# axi-ethernet register map
File version: 7.2
axi-ethernet device descript
Registers are 32-bit, read-only, reset 0x0 unless marked. A register's access mark holds for its fields unless they carry their own. Offsets are from the block's base; lines under a group give offsets from that group; [hi:lo] are bit positions; {n}, {i} and the like mark numbered series; 'fields as' and 'values as' point back to an identical list; <NAME> marks a mode.

## Memory map
0x60110000 AXI_ETHERNET size 0x10000 — AXI Ethernet MAC

## AXI_ETHERNET — AXI Ethernet MAC
Base 0x60110000
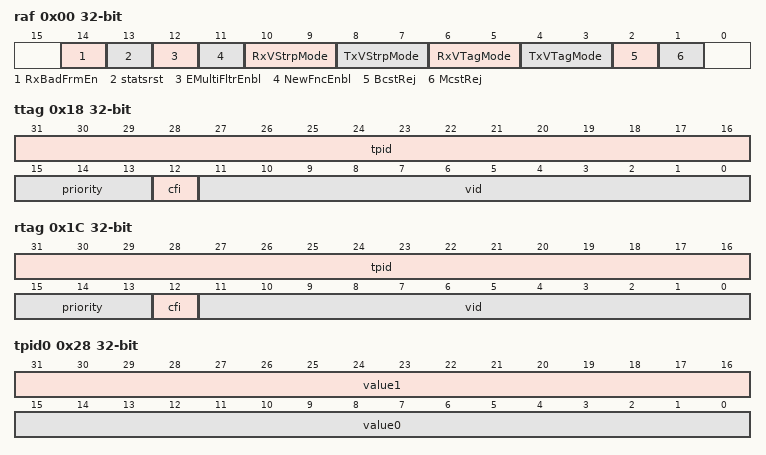
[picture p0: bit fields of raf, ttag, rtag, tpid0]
0x00 raf rw — Reset and Address Filter TEMAC
  [14] RxBadFrmEn
    0=DISABLE; 1=ENABLE
  [13] statsrst
    0=DISABLE; 1=ENABLE
  [12] EMultiFltrEnbl
    0=DISABLE; 1=ENABLE
  [11] NewFncEnbl
    0=DISABLE; 1=ENABLE
  [10:9] RxVStrpMode
    0=NO_VLAN; 1=ONE_VLAN_FROM_ALL; 3=ONE_VLAN_FROM_SELECT
  [8:7] TxVStrpMode
    0=NO_VLAN; 1=ONE_VLAN_FROM_ALL; 3=ONE_VLAN_FROM_SELECT
  [6:5] RxVTagMode
    0=NO_VLAN; 1=ONE_VLAN_FROM_ALL; 2=ONE_VLAN_FROM_ALL_HAVE; 3=ONE_VLAN_FROM_SELECT
  [4:3] TxVTagMode
    values as RxVTagMode
  [2] BcstRej
    0=ACCEPT; 1=REJECT
  [1] McstRej
    0=ACCEPT; 1=REJECT
0x04 tpf rw — Transmit Pause Frame TEMAC
  [15:0] TPFV
    0=RESET
0x08 ifgp rw — Transmit Inter Frame Gap Adjustment TEMAC
  [7:0] IFGP0
    0=RESET
0x0C is rw — Interrupt Status
  [8] PhyRstCmplt
    0=NOT_READY; 1=READY
  [7] MgtRdy
    0=NOT_READY; 1=READY
  [6] RxDcmLock
    0=NOT_LOCKED; 1=LOCKED
  [5] TxCmplt
    0=NO_FRAME; 1=HAS_FRAME
  [4] RxFIFOOvr
    0=NORMAL; 1=OVERFLOW
  [3] RxRject
    0=NO_REJECT; 1=HAS_REJECT
  [2] RxCmplt
    0=NO_FRAME; 1=HAS_FRAME
  [1] AutoNeg
    0=NOT_COMPLETE; 1=COMPLETE
  [0] HardAcsCmplt
    0=NOT_COMPLETE; 1=COMPLETE
  [5:0] All
0x10 ip — Interrupt Pending
  fields as is
0x14 ie rw — Interrupt Enable
  [8] PhyRstCmplt
    0=DISABLE; 1=ENABLE
  [7] MgtRdy
    0=DISABLE; 1=ENABLE
  [6] RxDcmLock
    0=DISABLE; 1=ENABLE
  [5] TxCmplt
    0=DISABLE; 1=ENABLE
  [4] RxFIFOOvr
    0=DISABLE; 1=ENABLE
  [3] RxRject
    0=DISABLE; 1=ENABLE
  [2] RxCmplt
    0=DISABLE; 1=ENABLE
  [1] AutoNeg
    0=DISABLE; 1=ENABLE
  [0] HardAcsCmplt
    0=DISABLE; 1=ENABLE
  [5:0] All
0x18 ttag rw — Transmit VLAN Tag TEMAC
  [all] fields
    0=RESET
  [31:16] tpid
  [15:13] priority
  [12] cfi
  [11:0] vid
0x1C rtag rw — Receive VLAN Tag TEMAC
  fields as ttag
0x20 uawl rw — Unicast Address Word Lower TEMAC
  [31:0] UnicastAddr
    0=RESET
0x24 uawu rw — Unicast Address Word Upper TEMAC
  [15:0] UnicastAddr
    0=RESET
0x28 tpid0 rw — VLAN TPID TEMAC Word 0
  [31:16] value1
    0=RESET
  [15:0] value0
    0=RESET
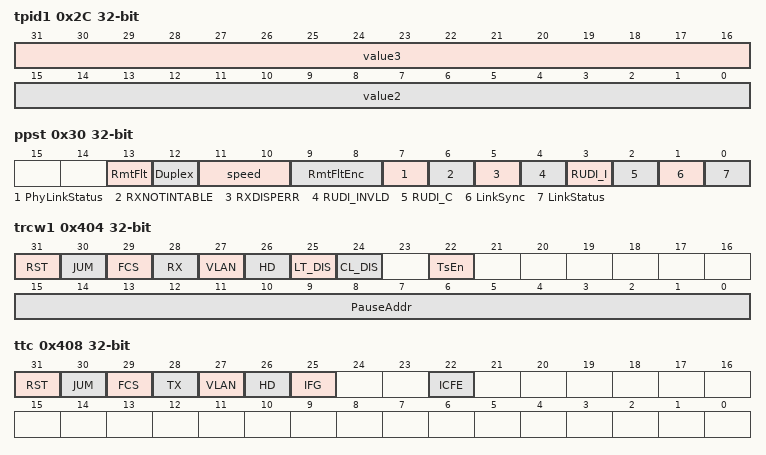
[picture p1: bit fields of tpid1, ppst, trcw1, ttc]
0x2C tpid1 rw — VLAN TPID TEMAC Word 1
  [31:16] value3
    0=RESET
  [15:0] value2
    0=RESET
0x30 ppst — PCS PMA TEMAC Status
  [13] RmtFlt
    0=RESET
  [12] Duplex
    0=HALF_DUPLEX; 1=FULL_DUPLEX
  [11:10] speed
    2=1000M; 1=100M; 0=10M
  [9:8] RmtFltEnc
    0=RESET
  [7] PhyLinkStatus
    0=RESET
  [6] RXNOTINTABLE
    0=RESET
  [5] RXDISPERR
    0=RESET
  [4] RUDI_INVLD
    0=RESET
  [3] RUDI_I
    0=RESET
  [2] RUDI_C
    0=RESET
  [1] LinkSync
    0=RESET
  [0] LinkStatus
    0=RESET
0x200 rxbl — Received Bytes, LSW
0x204 rxbu — Received Bytes, MSW
0x208 txbl — Transmitted Bytes, LSW
0x20C txbu — Transmitted Bytes, MSW
0x210 rxundrl — Count of undersize frames received, LSM
0x214 rxundru — Count of undersize frames received, MSM
0x218 rxfragl — Count of undersize and bad FCS frames received, LSM
0x21C rxfragu — Count of undersize and bad FCS frames received, MSM
0x220 rx64bl — Count of 64 bytes frames received, LSM
0x224 rx64bu — Count of 64 bytes frames received, MSM
0x228 rx65b127l — Count of 65-127 bytes frames received, LSM
0x22C rx65b127u — Count of 65-127 bytes frames received, MSM
0x230 rx128b255l — Count of 128-255 bytes frames received, LSM
0x234 rx128b255u — Count of 128-255 bytes frames received, MSM
0x238 rx256b511l — Count of 256-511 bytes frames received, LSM
0x23C rx256b511u — Count of 256-511 bytes frames received, MSM
0x240 rx512b1023l — Count of 512-1023 bytes frames received, LSM
0x244 rx512b1023u — Count of 512-1023 bytes frames received, MSM
0x248 rx1024bl — Count of 1024-MAX bytes frames received, LSM
0x24C rx1024bu — Count of 1024-MAX bytes frames received, MSM
0x250 rxovrl — Count of oversize frames received, LSM
0x254 rxovru — Count of oversize bytes frames received, MSM
0x258 tx64bl — Count of 64 bytes frames transmitted, LSM
0x25C tx64bu — Count of 64 bytes frames transmitted, MSM
0x260 tx65b127l — Count of 65-127 bytes frames transmitted, LSM
0x264 tx65b127u — Count of 65-127 bytes frames transmitted, MSM
0x268 tx128b255l — Count of 128-255 bytes frames transmitted, LSM
0x26C tx128b255u — Count of 128-255 bytes frames transmitted, MSM
0x270 tx256b511l — Count of 256-511 bytes frames transmitted, LSM
0x274 tx256b511u — Count of 256-511 bytes frames transmitted, MSM
0x278 tx512b1023l — Count of 512-1023 bytes frames transmitted, LSM
0x27C tx512b1023u — Count of 512-1023 bytes frames transmitted, MSM
0x280 tx1024bl — Count of 1024-MAX bytes frames transmitted, LSM
0x284 tx1024bu — Count of 1024-MAX bytes frames transmitted, MSM
0x288 txovrl — Count of oversize frames transmitted, LSM
0x28C txovru — Count of oversize bytes frames transmitted, MSM
0x290 rxfl — Count of frames received OK, LSM
0x294 rxfu — Count of frames transmitted OK, MSM
0x298 rxfcserl — Count of frames received with FCS error and at least 64 bytes, LSM
0x29C rxfcseru — Count of frames received with FCS error and at least 64 bytes, MSM
0x2A0 rxbcstfl — Count of broadcast frames received, LSM
0x2A4 rxbcstfu — Count of broadcast frames received, MSM
0x2A8 rxmcstfl — Count of multicast frames received, LSM
0x2AC rxmcstfu — Count of multicast frames received, MSM
0x2B0 rxctrfl — Count of control frames received, LSM
0x2B4 rxctrfu — Count of control frames received, MSM
0x2B8 rxlterl — Count of frames received with length error, LSM
0x2BC rxlteru — Count of frames received with length error, MSM
0x2C0 rxvlanfl — Count of VLAN tagged frames received, LSM
0x2C4 rxvlanfu — Count of VLAN tagged frames received, MSM
0x2C8 rxpfl — Count of pause frames received, LSM
0x2CC rxpfu — Count of pause frames received, MSM
0x2D0 rxuopfl — Count of control frames received with unsupported opcode, LSM
0x2D4 rxuopfu — Count of control frames received with unsupported opcode, MSM
0x2D8 txfl — Count of frames transmitted OK, LSM
0x2DC txfu — Count of frames transmitted OK, MSM
0x2E0 txbcstfl — Count of broadcast frames transmitted, LSM
0x2E4 txbcstfu — Count of broadcast frames transmitted, MSM
0x2E8 txmcstfl — Count of multicast frames transmitted, LSM
0x2EC txmcstfu — Count of multicast frames transmitted, MSM
0x2F0 txundererl — Count of frames transmitted underrun error, LSM
0x2F4 txundereru — Count of frames transmitted underrun error, MSM
0x2F8 txctrfl — Count of control frames transmitted, LSM
0x2FC txctrfu — Count of control frames transmitted, MSM
0x300 txvlanfl — Count of VLAN tagged frames transmitted, LSM
0x304 txvlanfu — Count of VLAN tagged frames transmitted, MSM
0x308 txpfl — Count of pause frames transmitted, LSM
0x30C txpfu — Count of pause frames transmitted, MSM
0x310 txscl — Single Collision frames transmitted OK, LSM
0x314 txscu — Single Collision frames transmitted OK, MSM
0x318 txmcl — Multiple Collision Frames Transmitted OK, LSM
0x31C txmcu — Multiple Collision frames Transmitted OK, MSM
0x320 txdefl — Deferred Tx Frames, LSM
0x324 txdefu — Deferred Tx Frames, MSM
0x328 txltcl — Frames transmitted with late Collisions, LSM
0x32C txltcu — Frames transmitted with late Collisions, MSM
0x330 txacel — Frames aborted with excessive Collisions, LSM
0x334 txaceu — Frames aborted with excessive Collisions, MSM
0x338 txedefl — Transmit Frames with excessive Defferal, LSM
0x33C txedefu — Transmit Frames with excessive Defferal, MSM
0x340 rxaerl — Frames received with alignment errors, LSM
0x34C rxaeru — Frames received with alignment errors, MSM
0x400 trcw0 rw — TEMAC Receive Configuration Word 0
0x404 trcw1 rw — TEMAC Receive Configuration Word 1
  [31] RST
    0=NO_RESET; 1=INIT_RESET
  [30] JUM
    0=DISABLE; 1=ENABLE
  [29] FCS
    0=STRIP; 1=NO_STRIP
  [28] RX
    0=DISABLE; 1=ENABLE
  [27] VLAN
    0=DISABLE; 1=ENABLE
  [26] HD
    0=FULL_DUPLEX; 1=HALF_DUPLEX
  [25] LT_DIS
    0=CHECK; 1=NOT_CHECK
  [24] CL_DIS
    0=RESET
  [22] TsEn
    0=RESET
  [15:0] PauseAddr
    0xFFFF=RESET
0x408 ttc rw — TEMAC Transmitter Configuration
  [31] RST
    0=NO_RESET; 1=INIT_RESET
  [30] JUM
    0=DISABLE; 1=ENABLE
  [29] FCS
    0=DISABLE; 1=ENABLE
  [28] TX
    0=DISABLE; 1=ENABLE
  [27] VLAN
    0=DISABLE; 1=ENABLE
  [26] HD
    0=FULL_DUPLEX; 1=HALF_DUPLEX
  [25] IFG
    0=DISABLE; 1=ENABLE
  [22] ICFE
    0=DISABLE; 1=ENABLE
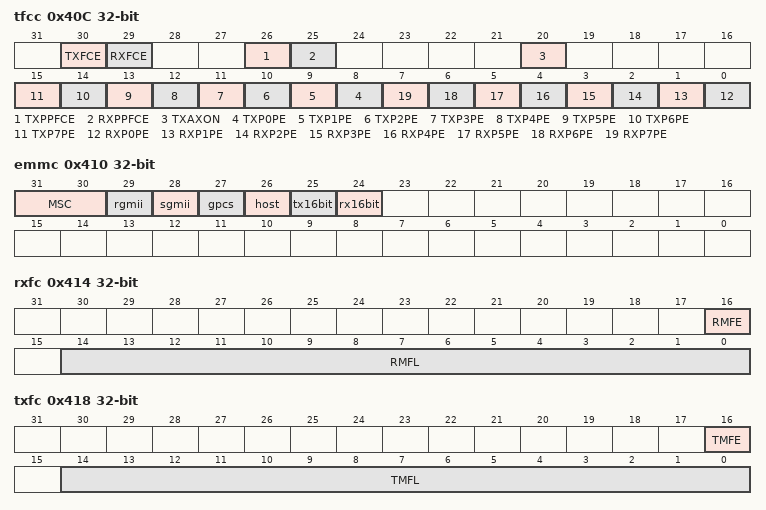
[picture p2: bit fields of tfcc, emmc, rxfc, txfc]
0x40C tfcc rw — TEMAC Flow Control Configuration
  [all] fields
    0=DISABLE; 1=ENABLE
  [30] TXFCE
  [29] RXFCE
  [26] TXPPFCE
  [25] RXPPFCE
  [20] TXAXON
  [n+8] TXP{n}PE (n=0..7)
  [n] RXP{n}PE (n=0..7)
0x410 emmc rw — EMAC mode configuration
  [31:30] MSC
    0=10M; 1=100M; 2=1000M
  [29] rgmii
    0=DISABLE; 1=ENABLE
  [28] sgmii
    0=DISABLE; 1=ENABLE
  [27] gpcs
    0=DISABLE; 1=ENABLE
  [26] host
    0=DISABLE; 1=ENABLE
  [25] tx16bit
    0=DISABLE; 1=ENABLE
  [24] rx16bit
    0=DISABLE; 1=ENABLE
0x414 rxfc rw — RX Max Frame Configuration
  [16] RMFE
    0=DISABLE; 1=ENABLE
  [14:0] RMFL
0x418 txfc rw — TX Max Frame Configuration
  [16] TMFE
    0=DISABLE; 1=ENABLE
  [14:0] TMFL
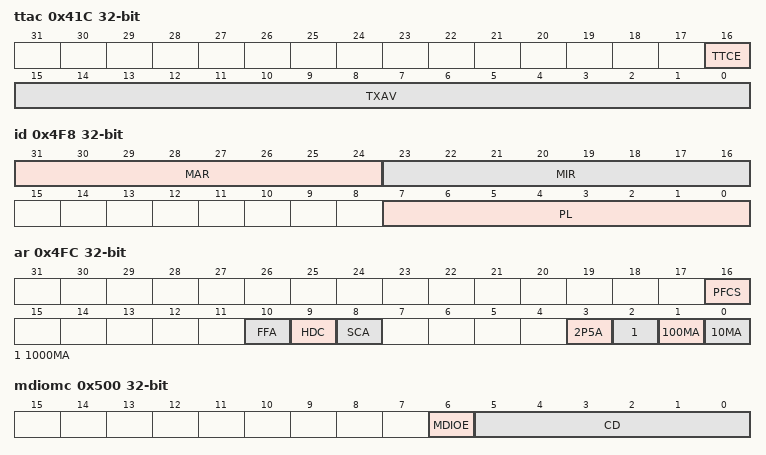
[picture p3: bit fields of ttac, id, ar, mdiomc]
0x41C ttac rw — TX Timestamp Adjust Control
  [16] TTCE
    0=DISABLE; 1=ENABLE
  [15:0] TXAV
0x420 phyc — RGMII/SGMII configuration
  [31:30] sgmiilinkspeed
    0=10M; 1=100M; 2=1000M
  [23:16] MIR
  [3:2] rgmiilinkspeed
    0=10M; 1=100M; 2=1000M
  [1] rgmiihd
  [0] rgmiilinkmask
  [7:0] PL
0x4F8 id — Identification
  [31:24] MAR, [23:16] MIR, [7:0] PL
0x4FC ar — Ability Register
  [all] fields
    0=DISABLE; 1=ENABLE
  [16] PFCS
  [10] FFA
  [9] HDC
  [8] SCA
  [3] 2P5A
  [2] 1000MA
  [1] 100MA
  [0] 10MA
0x500 mdiomc rw — MDIO Setup
  [6] MDIOE
    0=DISABLE; 1=ENABLE
  [5:0] CD
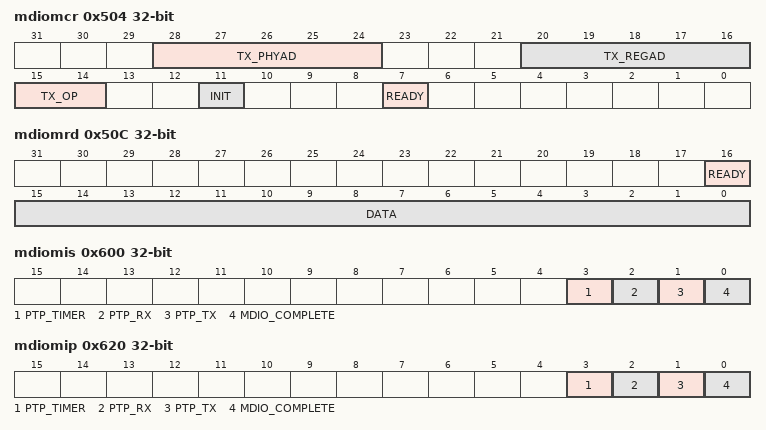
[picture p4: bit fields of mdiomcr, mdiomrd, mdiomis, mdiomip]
0x504 mdiomcr rw — MDIO Control
  [28:24] TX_PHYAD
  [20:16] TX_REGAD
  [15:14] TX_OP
    1=WA; 2=RA
  [11] INIT
    1=START
  [7] READY
    0=NOR_READY; 1=READY
0x508 mdiomwd rw — MDIO Write Data
  [15:0] DATA
0x50C mdiomrd rw — MDIO Read Data
  [16] READY, [15:0] DATA
0x600 mdiomis rw — MII Management Interrupt Status
  [all] fields
    0=NO_INTR; 1=HAS_INTR
  [3] PTP_TIMER
  [2] PTP_RX
  [1] PTP_TX
  [0] MDIO_COMPLETE
0x620 mdiomip — MII Management Interrupt Pending
  fields as mdiomis
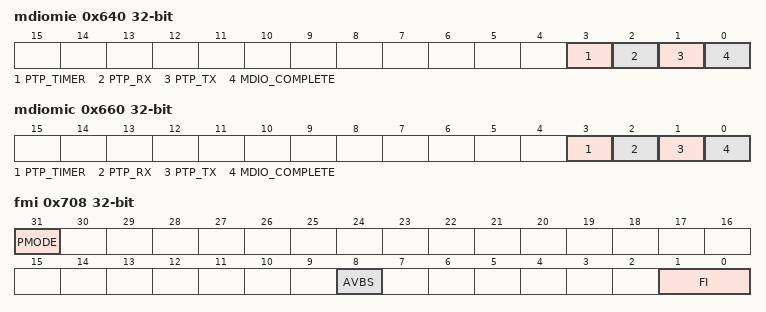
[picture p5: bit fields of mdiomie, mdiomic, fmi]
0x640 mdiomie rw — MII Management Interrupt Enable
  [all] fields
    0=DISABALE; 1=ENABLE
  [3] PTP_TIMER
  [2] PTP_RX
  [1] PTP_TX
  [0] MDIO_COMPLETE
0x660 mdiomic rw — MII Management Interrupt Clear
  [all] fields
    1=CLEAR
  [3] PTP_TIMER
  [2] PTP_RX
  [1] PTP_TX
  [0] MDIO_COMPLETE
0x700 uaw0 rw — Unicast Address Word 0 (UAW0)
  [31:0] address
0x704 uaw1 rw — Unicast Address Word 1 (UAW0)
  [15:0] address47T32
0x708 fmi rw — Filter Mask Index
  [31] PMODE
    0=DISBALE; 1=ENABLE
  [8] AVBS
    0=DISBALE; 1=ENABLE
  [1:0] FI
0x710 af0 rw — Address Filter 0
  [15:0] address47T32
0x714 af1 rw — Address Filter 1
0x2000 mcasttable rw — Multicast table address
0x4000 txvlandata rw — TX VLAN data table address
0x8000 rxvlandata rw — RX VLAN data table address
